# M3351 register map
File version: 1.0
Registers are 32-bit, read-write, reset 0x0 unless marked. A register's access mark holds for its fields unless they carry their own. Offsets are from the block's base; [hi:lo] are bit positions; {n}, {i} and the like mark numbered series; 'fields as' and 'values as' point back to an identical list.

## GPIO — GPIO Register Map
Base 0x40004000
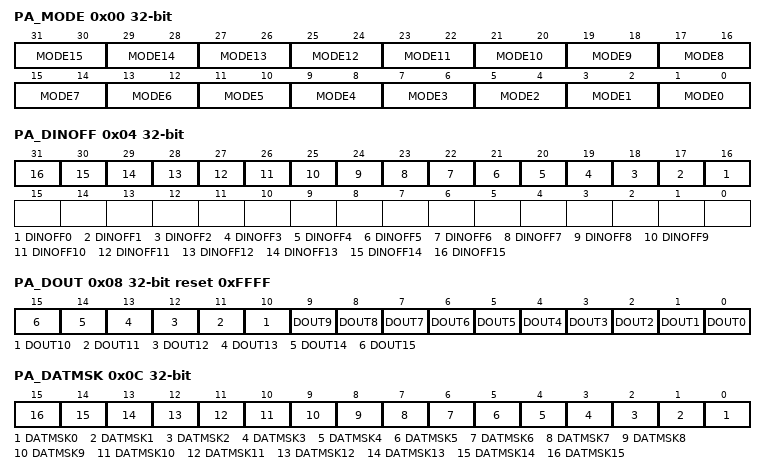
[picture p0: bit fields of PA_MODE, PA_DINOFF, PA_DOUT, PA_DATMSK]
0x00 PA_MODE — PA I/O Mode Control
  [all] fields
    0=Px.n is in Input mode; 1=Px.n is in Push-pull Output mode; 2=Px.n is in Open-drain Output mode; 3=Px.n is in Quasi-bidirectional mode
  [2n+1:2n] MODE{n} (n=0..15) — Port A-H I/O Pin[n] Mode Control. Determine each I/O mode of Px.n pins. Note: For more information about Px.n, please refer to the 'PIN CONFIGURATION' chapter.
0x04 PA_DINOFF — PA Digital Input Path Disable Control
  [all] fields
    0=Px.n digital input path Enabled; 1=Px.n digital input path Disabled (digital input tied to low)
  [n+16] DINOFF{n} (n=0..15) — Port A-H Pin[n] Digital Input Path Disable Bit. Each of these bits is used to control if the digital input path of corresponding Px.n pin is disabled. If input is analog signal, users can disable Px.n digital input path to avoid input current leakage. Note: For more information about Px.n, please refer to the 'PIN CONFIGURATION' chapter.
0x08 PA_DOUT reset 0xFFFF — PA Data Output Value
  [all] fields
    0=Px.n will drive Low if the Px.n pin is configured as Push-pull output, Open-drain output or Quasi-bidirectional mode; 1=Px.n will drive High if the Px.n pin is configured as Push-pull output or Quasi-bidirectional mode
  [n] DOUT{n} (n=0..15) — Port A-H Pin[n] Output Value. Each of these bits controls the status of a Px.n pin when the Px.n is configured as Push-pull output, Open-drain output or Quasi-bidirectional mode. Note: For more information about Px.n, please refer to the 'PIN CONFIGURATION' chapter.
0x0C PA_DATMSK — PA Data Output Write Mask
  [all] fields
    0=Corresponding DOUT (Px_DOUT[n]) bit can be updated; 1=Corresponding DOUT (Px_DOUT[n]) bit protected
  [n] DATMSK{n} (n=0..15) — Port A-H Pin[n] Data Output Write Mask. These bits are used to protect the corresponding DOUT (Px_DOUT[n]) bit. When the DATMSK (Px_DATMSK[n]) bit is set to 1, the corresponding DOUT (Px_DOUT[n]) bit is protected. If the write signal is masked, writing data to the protect bit is ignored. Note 1: This function only protects the corresponding DOUT (Px_DOUT[n]) bit, and will not protect the corresponding PDIO (Pxn_PDIO[0]) bit. Note 2: For more information about Px.n, please refer to the 'PIN CONFIGURATION' chapter.
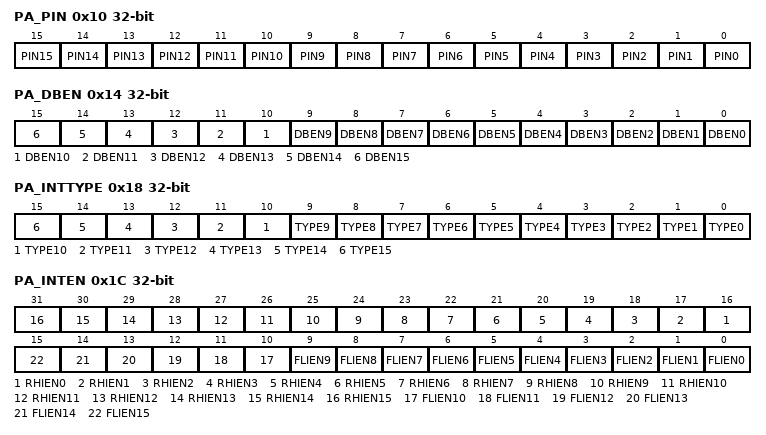
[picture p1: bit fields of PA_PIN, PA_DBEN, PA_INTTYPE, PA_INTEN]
0x10 PA_PIN ro (reset mask 0xFFFF0000) — PA Pin Value
  [n] PIN{n} (n=0..15) — Port A-H Pin[n] Pin Value. Each bit of the register reflects the actual status of the respective Px.n pin. If the bit is 1, it indicates the corresponding pin status is high; else the pin status is low. Note: For more information about Px.n, please refer to the 'PIN CONFIGURATION' chapter.
0x14 PA_DBEN — PA De-bounce Enable Control Register
  [all] fields
    0=Px.n de-bounce function Disabled; 1=Px.n de-bounce function Enabled
  [n] DBEN{n} (n=0..15) — Port A-H Pin[n] Input Signal De-bounce Enable Bit. The DBEN[n] bit is used to enable the de-bounce function for each corresponding bit. If the input signal pulse width cannot be sampled by continuous two de-bounce sample cycle, the input signal transition is seen as the signal bounce and will not trigger the interrupt. The de-bounce clock source is controlled by DBCLKSRC (Px_DBCTL [4]), one de-bounce sample cycle period is controlled by DBCLKSEL (Px_DBCTL [3:0]). The de-bounce function is valid only for edge triggered interrupt. If the interrupt mode is level triggered, the de-bounce enable bit is ignored. Note: For more information about Px.n, please refer to the 'PIN CONFIGURATION' chapter.
0x18 PA_INTTYPE — PA Interrupt Trigger Type Control
  [all] fields
    0=Edge trigger interrupt; 1=Level trigger interrupt
  [n] TYPE{n} (n=0..15) — Port A-H Pin[n] Edge or Level Detection Interrupt Trigger Type Control. TYPE (Px_INTTYPE[n]) bit is used to control the triggered interrupt is by level trigger or by edge trigger. If the interrupt is by edge trigger, the trigger source can be controlled by de-bounce. If the interrupt is by level trigger, the input source is sampled by one HCLK clock and generates the interrupt. If the pin is set as the level trigger interrupt, only one level can be set on the registers RHIEN (Px_INTEN[n+16])/FLIEN (Px_INTEN[n]). If both levels to trigger interrupt are set, the setting is ignored and no interrupt will occur. The de-bounce function is valid only for edge triggered interrupt. If the interrupt mode is level triggered, the de-bounce enable bit is ignored. Note: For more information about Px.n, please refer to the 'PIN CONFIGURATION' chapter.
0x1C PA_INTEN — PA Interrupt Enable Control Register
  [n+16] RHIEN{n} (n=0..15) — Port A-H Pin[n] Rising Edge or High Level Interrupt Trigger Type Enable Bit. The RHIEN (Px_INTEN[n+16]) bit is used to enable the interrupt for each of the corresponding input Px.n pin. Set bit to 1 also enable the pin wake-up function. When setting the RHIEN (Px_INTEN[n+16]) bit to 1 : If the interrupt is level trigger (TYPE (Px_INTTYPE[n]) bit is set to 1), the input Px.n pin will generate the interrupt while this pin state is at high level. If the interrupt is edge trigger (TYPE (Px_INTTYPE[n]) bit is set to 0), the input Px.n pin will generate the interrupt while this pin state changed from low to high. Note: For more information about Px.n, please refer to the 'PIN CONFIGURATION' chapter.
    0=Px.n level high or low to high interrupt Disabled; 1=Px.n level high or low to high interrupt Enabled
  [n] FLIEN{n} (n=0..15) — Port A-H Pin[n] Falling Edge or Low Level Interrupt Trigger Type Enable Bit. The FLIEN (Px_INTEN[n]) bit is used to enable the interrupt for each of the corresponding input Px.n pin. Set bit to 1 also enable the pin wake-up function. When setting the FLIEN (Px_INTEN[n]) bit to 1: If the interrupt is level trigger (TYPE (Px_INTTYPE[n]) bit is set to 1), the input Px.n pin will generate the interrupt while this pin state is at low level. If the interrupt is edge trigger (TYPE (Px_INTTYPE[n]) bit is set to 0), the input Px.n pin will generate the interrupt while this pin state changed from high to low. Note: For more information about Px.n, please refer to the 'PIN CONFIGURATION' chapter.
    0=Px.n level low or high to low interrupt Disabled; 1=Px.n level low or high to low interrupt Enabled
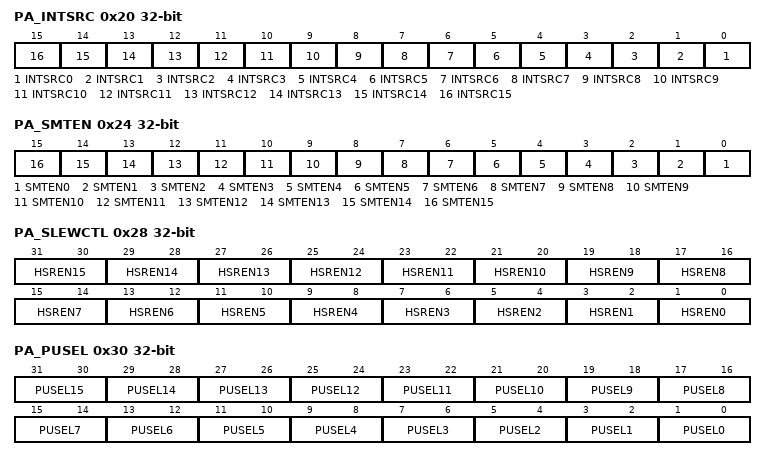
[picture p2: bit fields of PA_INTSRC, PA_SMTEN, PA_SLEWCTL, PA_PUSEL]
0x20 PA_INTSRC (reset mask 0xFFFF0000) — PA Interrupt Source Flag
  [all] fields
    0=No action. No interrupt at Px.n; 1=Clear the corresponding pending interrupt. Px.n generates an interrupt
  [n] INTSRC{n} (n=0..15) — Port A-H Pin[n] Interrupt Source Flag. Write Operation: Note: For more information about Px.n, please refer to the 'PIN CONFIGURATION' chapter.
0x24 PA_SMTEN — PA Input Schmitt Trigger Enable Register
  [all] fields
    0=Px.n input schmitt trigger function Disabled; 1=Px.n input schmitt trigger function Enabled
  [n] SMTEN{n} (n=0..15) — Port A-H Pin[n] Input Schmitt Trigger Enable Bit. Note: For more information about Px.n, please refer to the 'PIN CONFIGURATION' chapter.
0x28 PA_SLEWCTL — PA High Slew Rate Control Register
  [all] fields
    0=Px.n output with normal slew rate mode; 1=Px.n output with high slew rate mode
  [2n+1:2n] HSREN{n} (n=0..15) — Port A-H Pin[n] High Slew Rate Control. Note 1: For more information about Px.n, please refer to the 'PIN CONFIGURATION' chapter. Note 2: Please refer to the Datasheet for detailed pin operation voltage information about VDD electrical characteristics.
0x30 PA_PUSEL — PA Pull-up and Pull-down Selection Register
  [all] fields
    0=Px.n pull-up and pull-down disable; 1=Px.n pull-up enable; 2=Px.n pull-down enable
  [2n+1:2n] PUSEL{n} (n=0..15) — Port A-H Pin[n] Pull-up and Pull-down Enable Register. Determine each I/O Pull-up/pull-down of Px.n pins. Note 1: Basically, the pull-up control and pull-down control has following behavior limitation: The independent pull-up control register only valid when MODEn set as tri-state and open-drain mode. The independent pull-down control register only valid when MODEn set as tri-state mode. When both pull-uppull-down is set as 1 at 'tri-state' mode, keep I/O in tri-state mode. Note 2: For more information about Px.n, please refer to the 'PIN CONFIGURATION' chapter.
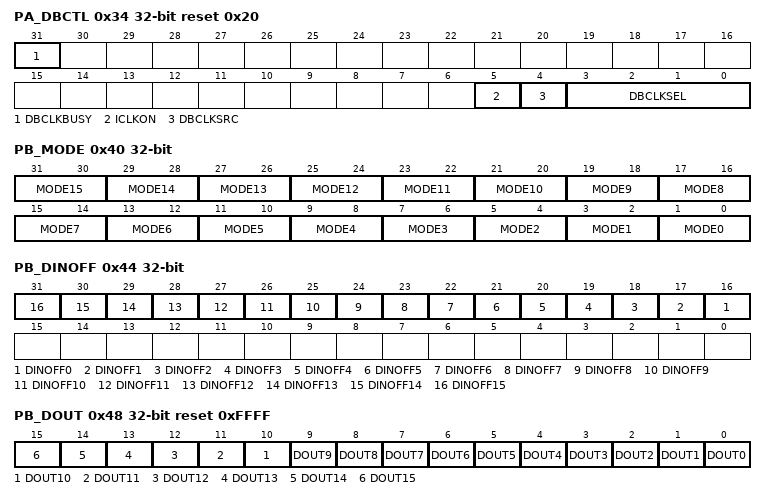
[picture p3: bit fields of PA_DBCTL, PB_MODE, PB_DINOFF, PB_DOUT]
0x34 PA_DBCTL reset 0x20 — PA Interrupt De-bounce Control Register
  [31] DBCLKBUSY — De-bounce Clock Switching Busy Flag. This bit is set when de-bounce clock source is changed by setting DBCLKSRC(Px_DBCTL[4]). And it is cleared after de-bounce clock source switching is finished. De-bounce function can work normally after de-bounce clock switch done. Note: Secure Only and Read Only.
    0=De-bounce clock switch done; 1=De-bounce clock is switching.N
  [5] ICLKON — Interrupt Clock on Mode. Note 1: It is recommended to disable this bit to save system power if no special application concern. Note 2: For more information about Px.n, please refer to the 'PIN CONFIGURATION' chapter. Notez: Secure Only and Read Only.
    0=Edge detection circuit is active only if I/O pin corresponding RHIEN (Px_INTEN[n+16])/FLIEN (Px_INTEN[n]) bit is set to 1. If corresponding RHIEN or FLIEN is 0, the clock of I/O detect circuit is stopped and interrupt source flag(Px_INTSRC) cannot be clear also; 1=All I/O pins edge detection circuit is always active after reset
  [4] DBCLKSRC — De-bounce Counter Clock Source Selection. Note: Secure Only.
    0=De-bounce counter clock source is the HCLK; 1=De-bounce counter clock source is the 38.4 kHz internal low speed RC oscillator (LIRC)
  [3:0] DBCLKSEL — De-bounce Sampling Cycle Selection. Note: Secure Only.
    0=Sample interrupt input once per 1 clocks; 1=Sample interrupt input once per 2 clocks; 2=Sample interrupt input once per 4 clocks; 3=Sample interrupt input once per 8 clocks; 4=Sample interrupt input once per 16 clocks; 5=Sample interrupt input once per 32 clocks; 6=Sample interrupt input once per 64 clocks; 7=Sample interrupt input once per 128 clocks; 8=Sample interrupt input once per 256 clocks; 9=Sample interrupt input once per 2*256 clocks; 10=Sample interrupt input once per 4*256 clocks; 11=Sample interrupt input once per 8*256 clocks; 12=Sample interrupt input once per 16*256 clocks; 13=Sample interrupt input once per 32*256 clocks; 14=Sample interrupt input once per 64*256 clocks; 15=Sample interrupt input once per 128*256 clocks
0x40 PB_MODE — PB I/O Mode Control
  fields as PA_MODE
0x44 PB_DINOFF — PB Digital Input Path Disable Control
  fields as PA_DINOFF
0x48 PB_DOUT reset 0xFFFF — PB Data Output Value
  fields as PA_DOUT
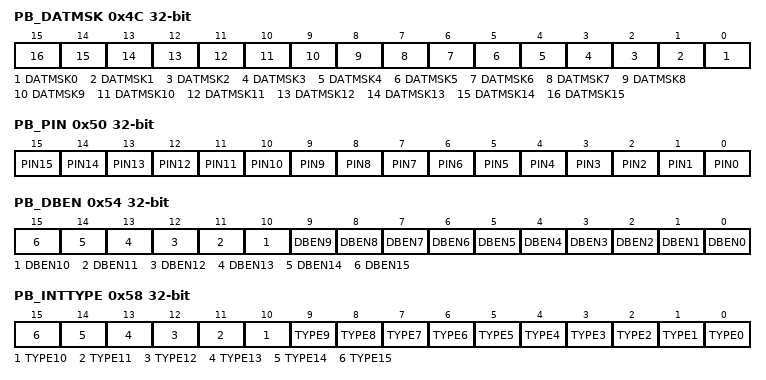
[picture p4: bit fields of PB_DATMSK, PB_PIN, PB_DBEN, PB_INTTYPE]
0x4C PB_DATMSK — PB Data Output Write Mask
  fields as PA_DATMSK
0x50 PB_PIN ro (reset mask 0xFFFF0000) — PB Pin Value
  fields as PA_PIN
0x54 PB_DBEN — PB De-bounce Enable Control Register
  fields as PA_DBEN
0x58 PB_INTTYPE — PB Interrupt Trigger Type Control
  fields as PA_INTTYPE
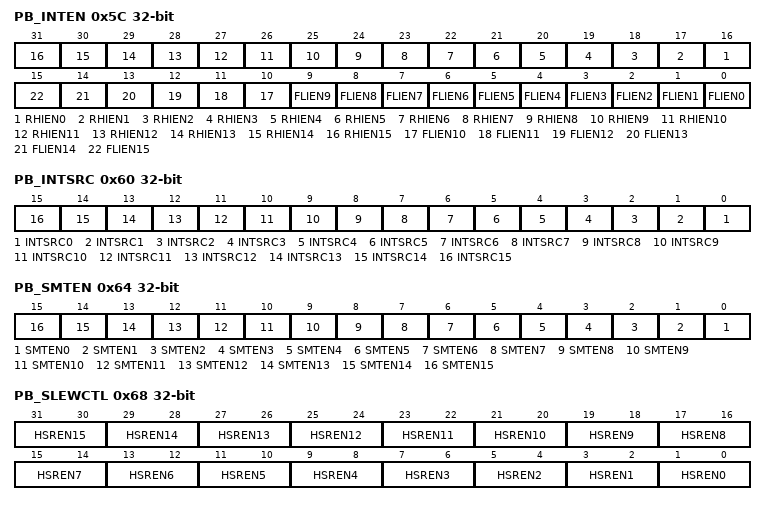
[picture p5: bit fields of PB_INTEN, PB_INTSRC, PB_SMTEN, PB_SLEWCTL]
0x5C PB_INTEN — PB Interrupt Enable Control Register
  fields as PA_INTEN
0x60 PB_INTSRC (reset mask 0xFFFF0000) — PB Interrupt Source Flag
  fields as PA_INTSRC
0x64 PB_SMTEN — PB Input Schmitt Trigger Enable Register
  fields as PA_SMTEN
0x68 PB_SLEWCTL — PB High Slew Rate Control Register
  fields as PA_SLEWCTL
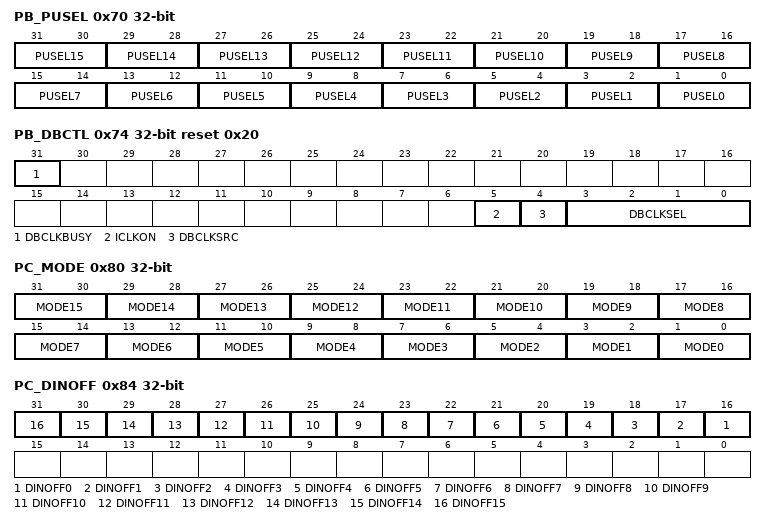
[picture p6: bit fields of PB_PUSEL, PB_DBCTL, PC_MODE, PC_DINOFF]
0x70 PB_PUSEL — PB Pull-up and Pull-down Selection Register
  fields as PA_PUSEL
0x74 PB_DBCTL reset 0x20 — PB Interrupt De-bounce Control Register
  fields as PA_DBCTL
0x80 PC_MODE — PC I/O Mode Control
  fields as PA_MODE
0x84 PC_DINOFF — PC Digital Input Path Disable Control
  fields as PA_DINOFF
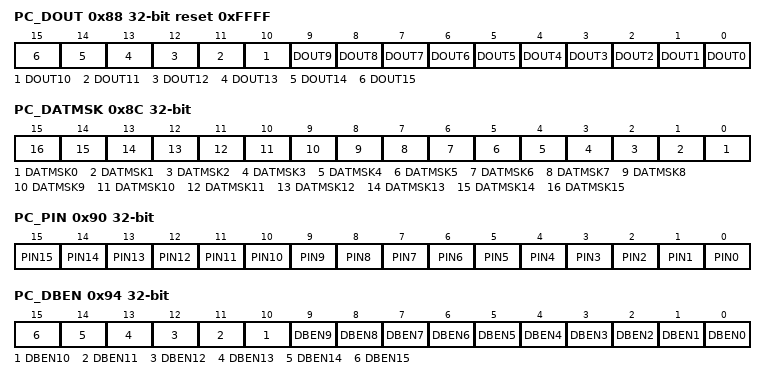
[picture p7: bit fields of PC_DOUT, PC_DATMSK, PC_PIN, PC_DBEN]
0x88 PC_DOUT reset 0xFFFF — PC Data Output Value
  fields as PA_DOUT
0x8C PC_DATMSK — PC Data Output Write Mask
  fields as PA_DATMSK
0x90 PC_PIN ro (reset mask 0xFFFF0000) — PC Pin Value
  fields as PA_PIN
0x94 PC_DBEN — PC De-bounce Enable Control Register
  fields as PA_DBEN
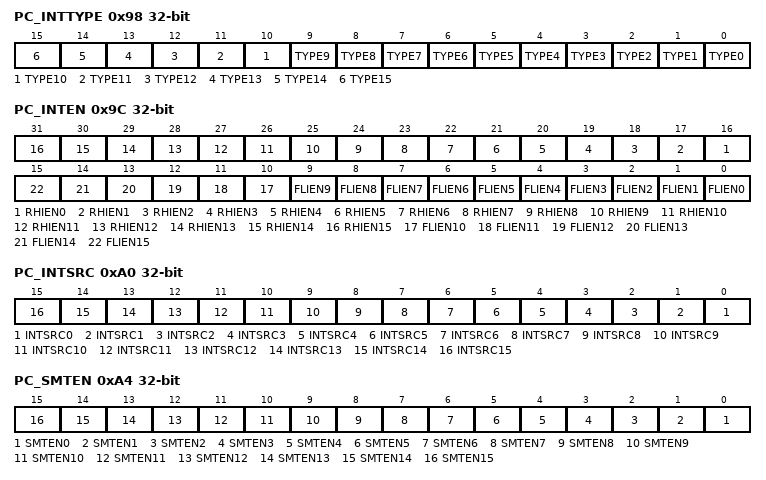
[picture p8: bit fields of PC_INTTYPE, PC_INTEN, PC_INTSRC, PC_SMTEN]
0x98 PC_INTTYPE — PC Interrupt Trigger Type Control
  fields as PA_INTTYPE
0x9C PC_INTEN — PC Interrupt Enable Control Register
  fields as PA_INTEN
0xA0 PC_INTSRC (reset mask 0xFFFF0000) — PC Interrupt Source Flag
  fields as PA_INTSRC
0xA4 PC_SMTEN — PC Input Schmitt Trigger Enable Register
  fields as PA_SMTEN
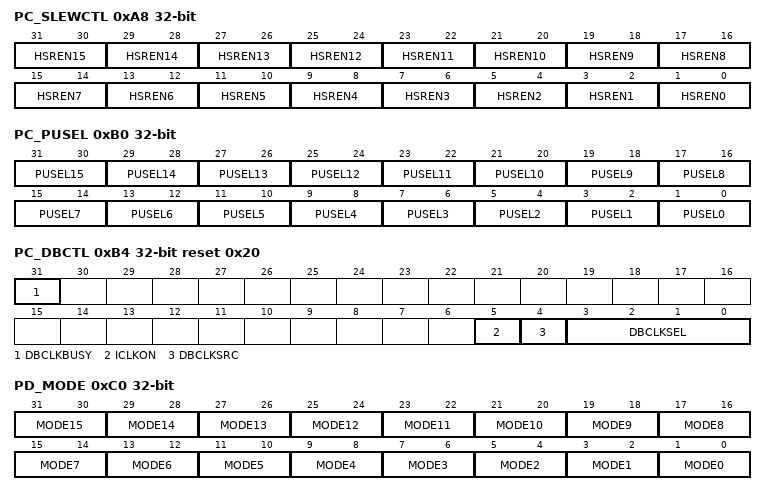
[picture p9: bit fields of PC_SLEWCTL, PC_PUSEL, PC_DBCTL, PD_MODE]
0xA8 PC_SLEWCTL — PC High Slew Rate Control Register
  fields as PA_SLEWCTL
0xB0 PC_PUSEL — PC Pull-up and Pull-down Selection Register
  fields as PA_PUSEL
0xB4 PC_DBCTL reset 0x20 — PC Interrupt De-bounce Control Register
  fields as PA_DBCTL
0xC0 PD_MODE — PD I/O Mode Control
  fields as PA_MODE
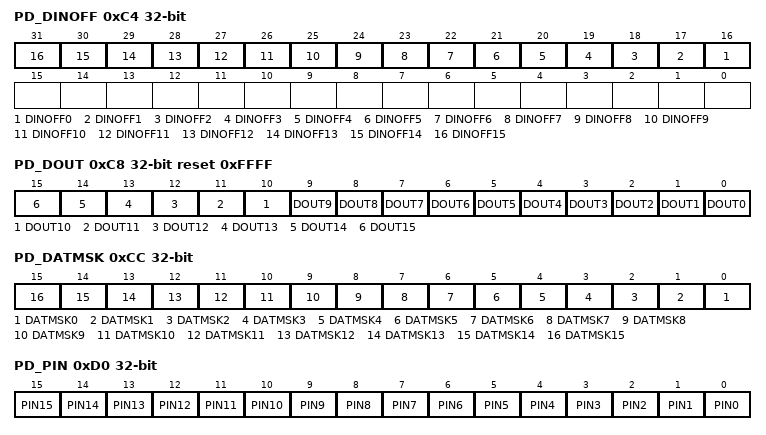
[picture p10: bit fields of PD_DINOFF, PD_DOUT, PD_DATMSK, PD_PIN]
0xC4 PD_DINOFF — PD Digital Input Path Disable Control
  fields as PA_DINOFF
0xC8 PD_DOUT reset 0xFFFF — PD Data Output Value
  fields as PA_DOUT
0xCC PD_DATMSK — PD Data Output Write Mask
  fields as PA_DATMSK
0xD0 PD_PIN ro (reset mask 0xFFFF0000) — PD Pin Value
  fields as PA_PIN
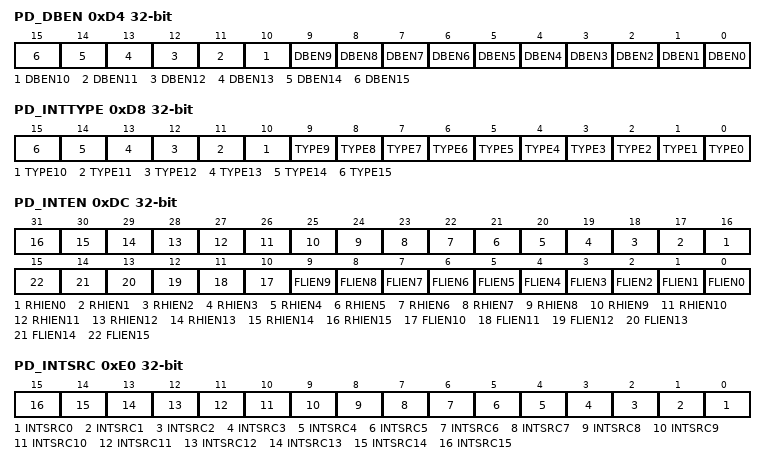
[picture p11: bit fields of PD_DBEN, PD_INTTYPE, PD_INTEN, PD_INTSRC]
0xD4 PD_DBEN — PD De-bounce Enable Control Register
  fields as PA_DBEN
0xD8 PD_INTTYPE — PD Interrupt Trigger Type Control
  fields as PA_INTTYPE
0xDC PD_INTEN — PD Interrupt Enable Control Register
  fields as PA_INTEN
0xE0 PD_INTSRC (reset mask 0xFFFF0000) — PD Interrupt Source Flag
  fields as PA_INTSRC
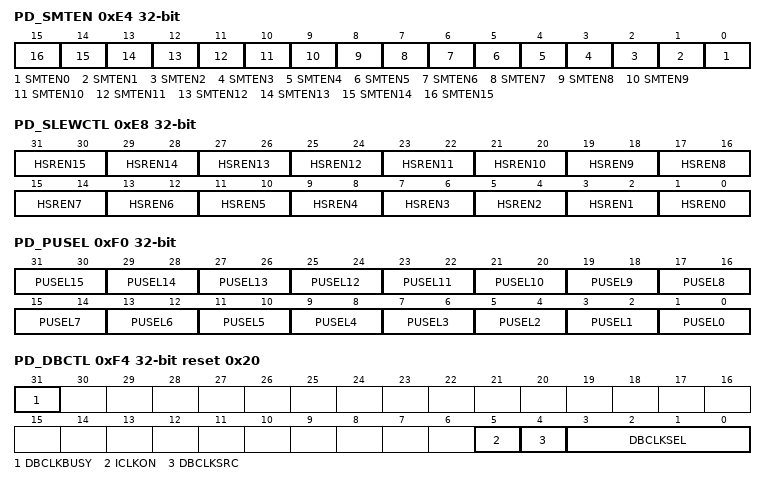
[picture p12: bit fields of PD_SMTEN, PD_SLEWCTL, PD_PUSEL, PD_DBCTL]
0xE4 PD_SMTEN — PD Input Schmitt Trigger Enable Register
  fields as PA_SMTEN
0xE8 PD_SLEWCTL — PD High Slew Rate Control Register
  fields as PA_SLEWCTL
0xF0 PD_PUSEL — PD Pull-up and Pull-down Selection Register
  fields as PA_PUSEL
0xF4 PD_DBCTL reset 0x20 — PD Interrupt De-bounce Control Register
  fields as PA_DBCTL
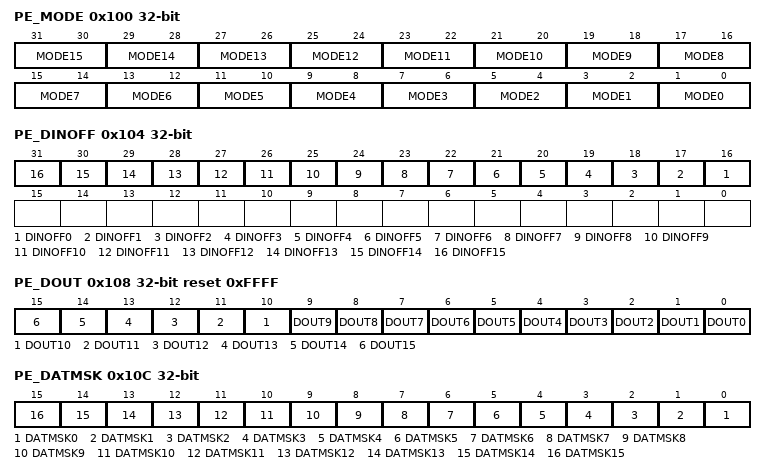
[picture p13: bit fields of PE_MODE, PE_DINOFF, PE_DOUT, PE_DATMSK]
0x100 PE_MODE — PE I/O Mode Control
  fields as PA_MODE
0x104 PE_DINOFF — PE Digital Input Path Disable Control
  fields as PA_DINOFF
0x108 PE_DOUT reset 0xFFFF — PE Data Output Value
  fields as PA_DOUT
0x10C PE_DATMSK — PE Data Output Write Mask
  fields as PA_DATMSK
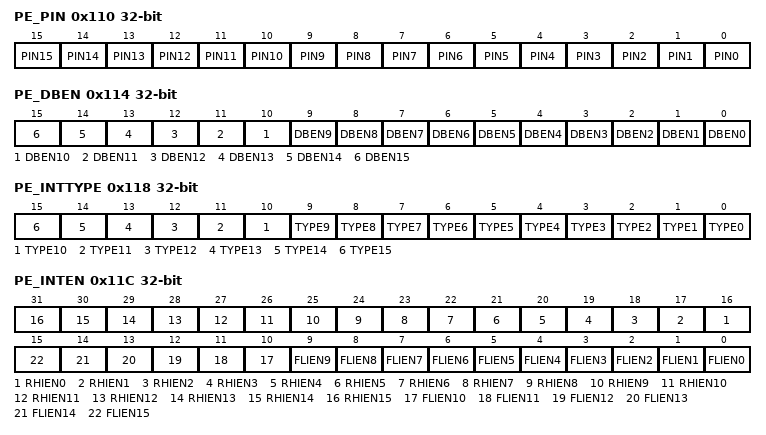
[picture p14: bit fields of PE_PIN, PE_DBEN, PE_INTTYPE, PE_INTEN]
0x110 PE_PIN ro (reset mask 0xFFFF0000) — PE Pin Value
  fields as PA_PIN
0x114 PE_DBEN — PE De-bounce Enable Control Register
  fields as PA_DBEN
0x118 PE_INTTYPE — PE Interrupt Trigger Type Control
  fields as PA_INTTYPE
0x11C PE_INTEN — PE Interrupt Enable Control Register
  fields as PA_INTEN
0x120 PE_INTSRC (reset mask 0xFFFF0000) — PE Interrupt Source Flag
  fields as PA_INTSRC
0x124 PE_SMTEN — PE Input Schmitt Trigger Enable Register
  fields as PA_SMTEN
0x128 PE_SLEWCTL — PE High Slew Rate Control Register
  fields as PA_SLEWCTL
0x130 PE_PUSEL — PE Pull-up and Pull-down Selection Register
  fields as PA_PUSEL
0x134 PE_DBCTL reset 0x20 — PE Interrupt De-bounce Control Register
  fields as PA_DBCTL
0x140 PF_MODE — PF I/O Mode Control
  fields as PA_MODE
0x144 PF_DINOFF — PF Digital Input Path Disable Control
  fields as PA_DINOFF
0x148 PF_DOUT reset 0xFFFF — PF Data Output Value
  fields as PA_DOUT
0x14C PF_DATMSK — PF Data Output Write Mask
  fields as PA_DATMSK
0x150 PF_PIN ro (reset mask 0xFFFF0000) — PF Pin Value
  fields as PA_PIN
0x154 PF_DBEN — PF De-bounce Enable Control Register
  fields as PA_DBEN
0x158 PF_INTTYPE — PF Interrupt Trigger Type Control
  fields as PA_INTTYPE
0x15C PF_INTEN — PF Interrupt Enable Control Register
  fields as PA_INTEN
0x160 PF_INTSRC (reset mask 0xFFFF0000) — PF Interrupt Source Flag
  fields as PA_INTSRC
0x164 PF_SMTEN — PF Input Schmitt Trigger Enable Register
  fields as PA_SMTEN
0x168 PF_SLEWCTL — PF High Slew Rate Control Register
  fields as PA_SLEWCTL
0x170 PF_PUSEL — PF Pull-up and Pull-down Selection Register
  fields as PA_PUSEL
0x174 PF_DBCTL reset 0x20 — PF Interrupt De-bounce Control Register
  fields as PA_DBCTL
0x180 PG_MODE — PG I/O Mode Control
  fields as PA_MODE
0x184 PG_DINOFF — PG Digital Input Path Disable Control
  fields as PA_DINOFF
0x188 PG_DOUT reset 0xFFFF — PG Data Output Value
  fields as PA_DOUT
0x18C PG_DATMSK — PG Data Output Write Mask
  fields as PA_DATMSK
0x190 PG_PIN ro (reset mask 0xFFFF0000) — PG Pin Value
  fields as PA_PIN
0x194 PG_DBEN — PG De-bounce Enable Control Register
  fields as PA_DBEN
0x198 PG_INTTYPE — PG Interrupt Trigger Type Control
  fields as PA_INTTYPE
0x19C PG_INTEN — PG Interrupt Enable Control Register
  fields as PA_INTEN
0x1A0 PG_INTSRC (reset mask 0xFFFF0000) — PG Interrupt Source Flag
  fields as PA_INTSRC
0x1A4 PG_SMTEN — PG Input Schmitt Trigger Enable Register
  fields as PA_SMTEN
0x1A8 PG_SLEWCTL — PG High Slew Rate Control Register
  fields as PA_SLEWCTL
0x1B0 PG_PUSEL — PG Pull-up and Pull-down Selection Register
  fields as PA_PUSEL
0x1B4 PG_DBCTL reset 0x20 — PG Interrupt De-bounce Control Register
  fields as PA_DBCTL
0x1C0 PH_MODE — PH I/O Mode Control
  fields as PA_MODE
0x1C4 PH_DINOFF — PH Digital Input Path Disable Control
  fields as PA_DINOFF
0x1C8 PH_DOUT reset 0xFFFF — PH Data Output Value
  fields as PA_DOUT
0x1CC PH_DATMSK — PH Data Output Write Mask
  fields as PA_DATMSK
0x1D0 PH_PIN ro (reset mask 0xFFFF0000) — PH Pin Value
  fields as PA_PIN
0x1D4 PH_DBEN — PH De-bounce Enable Control Register
  fields as PA_DBEN
0x1D8 PH_INTTYPE — PH Interrupt Trigger Type Control
  fields as PA_INTTYPE
0x1DC PH_INTEN — PH Interrupt Enable Control Register
  fields as PA_INTEN
0x1E0 PH_INTSRC (reset mask 0xFFFF0000) — PH Interrupt Source Flag
  fields as PA_INTSRC
0x1E4 PH_SMTEN — PH Input Schmitt Trigger Enable Register
  fields as PA_SMTEN
0x1E8 PH_SLEWCTL — PH High Slew Rate Control Register
  fields as PA_SLEWCTL
0x1F0 PH_PUSEL — PH Pull-up and Pull-down Selection Register
  fields as PA_PUSEL
0x1F4 PH_DBCTL reset 0x20 — PH Interrupt De-bounce Control Register
  fields as PA_DBCTL
{0x440+0x20*i} INT{i}_INNF (i=0..7) — INT{i} Input Noise Filter Register
  [10:8] NFCNT — Noise Filter Count. The register bits control the filter counter to count from 0 to NFCNT.
  [6:4] NFSEL — Noise Filter Clock Selection
    0=Filter clock is HCLK; 1=Filter clock is HCLK/2; 2=Filter clock is HCLK/4; 3=Filter clock is HCLK/8; 4=Filter clock is HCLK/16; 5=Filter clock is HCLK/32; 6=Filter clock is HCLK/64; 7=Filter clock is HCLK/128
  [0] NFEN — Noise Filter Enable Bit
    0=Noise Filter function Disabled; 1=Noise Filter function Enabled
{0x444+0x20*i} INT{i}_EDETCTL (i=0..7) — INT{i} Edge Detect Control Register
  [1:0] EDETCTL — INT Edge Detect Control Bits
    0=Not detect; 1=INT low to high detection Enabled; 2=INT high to low detection Enabled; 3=INT both low to high and high to low detection Enabled
{0x448+0x20*i} INT{i}_EDINTEN (i=0..7) — INT{i} Edge Detect Interrupt Enable Control Register
  [0] EDIEN — INT Edge Detect Interrupt Enable Bit
    0=INT Edge Detect Interrupt Disabled; 1=INT Edge Detect Interrupt Enabled
{0x44C+0x20*i} INT{i}_EDSTS (i=0..7) — INT{i} Edge Detect Interrupt Flag Register
  [0] EDIF — INT Edge Detect Interrupt Flag. Note: This bit is cleared by writing 1 to it.
    0=No Edge Detection happened; 1=Rising Edge or Falling edge has been detected
{0x800+4i} PA{i}_PDIO (reset mask 0xFFFFFFF0) (i=0..15) — GPIO PA.n Pin Data Input/Output Register
  [0] PDIO — GPIO Px.n Pin Data Input/Output. Writing this bit can control one GPIO pin output value. Read this register to get GPIO pin status. For example, writing PA0_PDIO will reflect the written value to bit DOUT (Px_DOUT[0]), reading PA0_PDIO will return the value of PIN (PA_PIN[0]). Note 1: The writing operation will not be affected by register DATMSK (Px_DATMSK[n]). Note 2: For more information about Px.n, please refer to the 'PIN CONFIGURATION' chapter.
    0=Corresponding GPIO pin set to low; 1=Corresponding GPIO pin set to high
{0x840+4i} PB{i}_PDIO (reset mask 0xFFFFFFF0) (i=0..15) — GPIO PB.n Pin Data Input/Output Register
  fields as PA0_PDIO
{0x880+4i} PC{i}_PDIO (reset mask 0xFFFFFFF0) (i=0..14) — GPIO PC.n Pin Data Input/Output Register
  fields as PA0_PDIO
{0x8C0+4i} PD{i}_PDIO (reset mask 0xFFFFFFF0) (i=0..14) — GPIO PD.n Pin Data Input/Output Register
  fields as PA0_PDIO
{0x900+4i} PE{i}_PDIO (reset mask 0xFFFFFFF0) (i=0..15) — GPIO PE.n Pin Data Input/Output Register
  fields as PA0_PDIO
{0x940+4i} PF{i}_PDIO (reset mask 0xFFFFFFF0) (i=0..15) — GPIO PF.n Pin Data Input/Output Register
  fields as PA0_PDIO
{0x980+4i} PG{i}_PDIO (reset mask 0xFFFFFFF0) (i=0..15) — GPIO PG.n Pin Data Input/Output Register
  fields as PA0_PDIO
{0x9C0+4i} PH{i}_PDIO (reset mask 0xFFFFFFF0) (i=0..11) — GPIO PH.n Pin Data Input/Output Register
  fields as PA0_PDIO

## GPIO_NS — GPIONS Register Map
Base 0x50004000
Registers as GPIO; these are added or differ:
{0x800+4i} PA{i}_PDIO (reset mask 0xFFFFFFF0) (i=0..15) — GPIO PA.n Pin Data Input/Output Register
  fields as GPIO.PA0_PDIO
{0x840+4i} PB{i}_PDIO (reset mask 0xFFFFFFF0) (i=0..15) — GPIO PB.n Pin Data Input/Output Register
  fields as GPIO.PA0_PDIO
{0x880+4i} PC{i}_PDIO (reset mask 0xFFFFFFF0) (i=0..14) — GPIO PC.n Pin Data Input/Output Register
  fields as GPIO.PA0_PDIO
{0x8C0+4i} PD{i}_PDIO (reset mask 0xFFFFFFF0) (i=0..14) — GPIO PD.n Pin Data Input/Output Register
  fields as GPIO.PA0_PDIO
{0x900+4i} PE{i}_PDIO (reset mask 0xFFFFFFF0) (i=0..15) — GPIO PE.n Pin Data Input/Output Register
  fields as GPIO.PA0_PDIO
{0x940+4i} PF{i}_PDIO (reset mask 0xFFFFFFF0) (i=0..15) — GPIO PF.n Pin Data Input/Output Register
  fields as GPIO.PA0_PDIO
{0x980+4i} PG{i}_PDIO (reset mask 0xFFFFFFF0) (i=0..15) — GPIO PG.n Pin Data Input/Output Register
  fields as GPIO.PA0_PDIO
{0x9C0+4i} PH{i}_PDIO (reset mask 0xFFFFFFF0) (i=0..11) — GPIO PH.n Pin Data Input/Output Register
  fields as GPIO.PA0_PDIO
